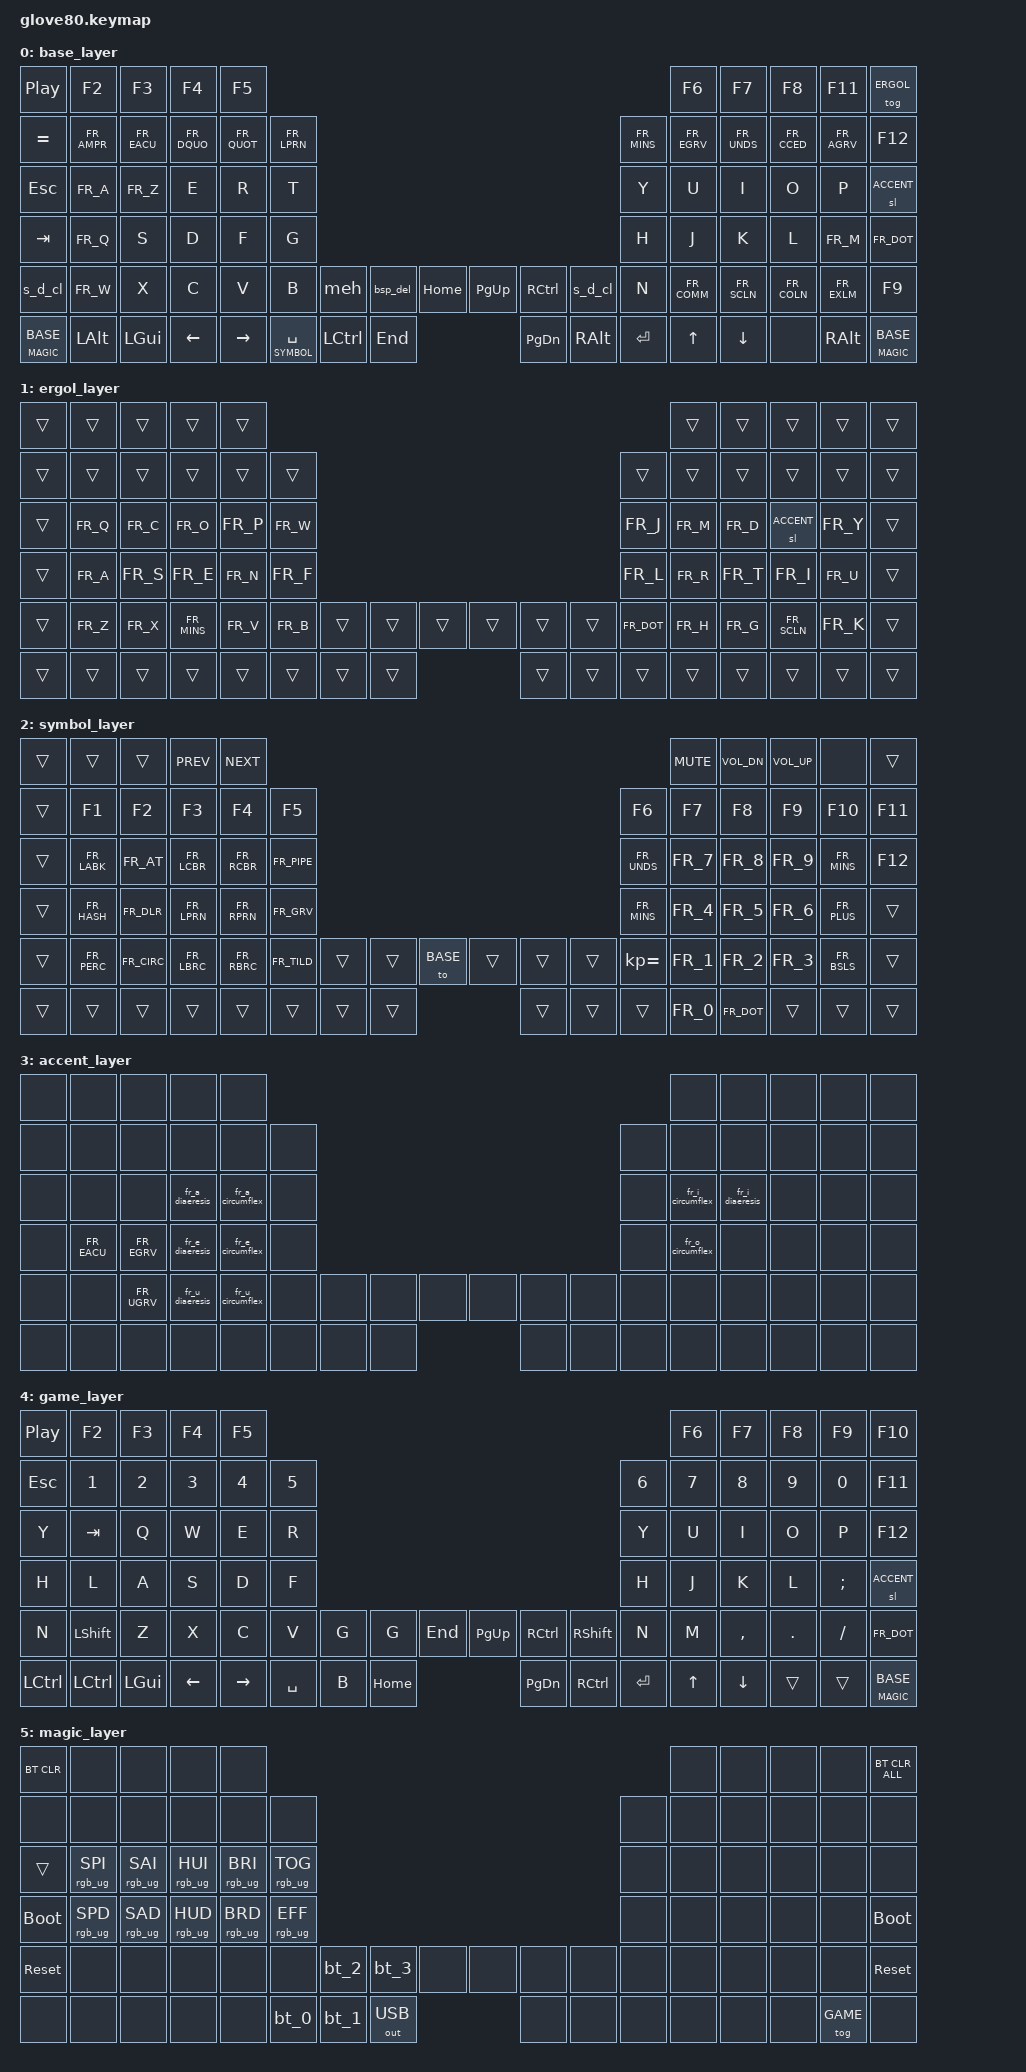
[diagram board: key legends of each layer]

/*
 * Copyright (c) 2020 The ZMK Contributors
 * Copyright (c) 2022 Innaworks Development Limited, trading as MoErgo
 *
 * SPDX-License-Identifier: MIT
 */


/* THIS FILE WAS GENERATED BY GLOVE80 LAYOUT EDITOR
 *
 * This file was generated automatically. You may or may not want to
 * edit it directly.
 */

#include <behaviors.dtsi>
/* Include all behaviour includes needed by system behaviors/macros */
#include <dt-bindings/zmk/outputs.h>

/* Include behaviour includes needed by key binds - automatically generated */
#include <dt-bindings/zmk/keys.h>
#include <dt-bindings/zmk/bt.h>
#include <dt-bindings/zmk/rgb.h>
#include <dt-bindings/zmk/outputs.h>


/* french helpers */
#ifndef KEYMAP_DRAWER
#include "keymap_french.h"
#endif

/*
Layers

Those numbers are meaningless.
The actual index of the layers is the one in keymap which are zero indexed.
*/
#define BASE    0
#define ERGOL   1
#define SYMBOL  2
#define ACCENT  3
#define GAME    4
#define MAGIC   5

/ {
    /* Glove80 system behavior & macros */
    behaviors {
        // For the "layer" key, it'd nice to be able to use it as either a shift or a toggle.
        // Configure it as a tap dance, so the first tap (or hold) is a &mo and the second tap is a &to
        lower: tap_dance_0 {
            compatible = "zmk,behavior-tap-dance";
            label = "LAYER_TAP_DANCE";
            #binding-cells = <0>;
            tapping-term-ms = <200>;
            bindings = <&mo SYMBOL>, <&to SYMBOL>;
        };

        s_d_cl: shift_double_capslock {
            compatible = "zmk,behavior-tap-dance";
            label = "shift_double_capslock";
            #binding-cells = <0>;
            tapping-term-ms = <200>;
            bindings = <&kp LSHIFT>, <&kp CAPSLOCK>;
        };

        bsp_del: backspace_delete {
            compatible = "zmk,behavior-mod-morph";
            #binding-cells = <0>;
            bindings = <&kp BSPC>, <&kp DEL>;
            mods = <(MOD_LSFT|MOD_RSFT)>;
        };
    };

    #define BT_MACRO(name)                  \
    bt_ ## name: bt_profile_macro_ ## name {\
        label = "BT_ ## name";              \
        compatible = "zmk,behavior-macro";  \
        #binding-cells = <0>;               \
        bindings                            \
            = <&out OUT_BLE>                \
            , <&bt BT_SEL name>;            \
    };

    macros {
        BT_MACRO(0)
        BT_MACRO(1)
        BT_MACRO(2)
        BT_MACRO(3)

        rgb_ug_status_macro: rgb_ug_status_macro_0 {
            label = "RGB_UG_STATUS";
            compatible = "zmk,behavior-macro";
            #binding-cells = <0>;
            bindings
                = <&rgb_ug RGB_STATUS>;
        };

        meh: meh_modifier {
            label = "MEH_MODIFIER";
            compatible = "zmk,behavior-macro";
            #binding-cells = <0>;
            bindings
                = <&macro_press &kp LS(LC(LALT))>
                , <&macro_pause_for_release>
                , <&macro_release &kp LS(LC(LALT))>
                ;
        };


    #define MACRO(name, keys)             \
    name: name##_macro {                  \
        label = #name;                    \
        compatible = "zmk,behavior-macro";\
        #binding-cells = <0>;             \
        tap-ms = <1>;                     \
        wait-ms = <1>;                    \
        bindings = <keys>;                \
    };

    // french accentuated letters
    #define diaeresis(name, key)    \
    MACRO(fr_ ## name ## _diaeresis, &kp FR_DIAE &kp key)

    #define circumflex(name, key)    \
    MACRO(fr_ ## name ## _circumflex, &kp FR_CIRC &kp key)

        circumflex(a, Q)
        circumflex(e, E)
        circumflex(i, I)
        circumflex(o, O)
        circumflex(u, U)
        diaeresis(a, Q)
        diaeresis(e, E)
        diaeresis(i, I)
        diaeresis(o, O)
        diaeresis(u, U)
    };

/* key positions for combos
From https://github.com/moergo-sc/zmk/blob/main/app/boards/arm/glove80/glove80.dtsi#L24-L29

0   1   2   3   4                                       5   6   7   8   9
10  11  12  13  14  15                              16  17  18  19  20  21
22  23  24  25  26  27                              38  39  50  31  32  33
34  35  36  37 (38) 39                              40 (41) 42  43  44  45  <- home row, and () are index
46  47  48  49  50  51    52 53 54    55  56  57    58  59  60  61  62  63
64  65  66  67  68        69 70 71    72  73  74        75  76  77  78  79

*/
/*
    combos {
      compatible = "zmk,combos";
      combo_ctrl_c {
        timeout-ms = <50>;
        // ring + middle finger on left hand
        key-positions = <36 37>;
        bindings = <&kp LC(C)>;
        layers = <BASE>;
      };
      combo_ctrl_v {
        timeout-ms = <50>;
        // middle finger + index on left hand
        key-positions = <37 38>;
        bindings = <&kp LC(V)>;
        layers = <BASE>;
      };
    };
*/

    magic: magic_hold_tap {
        compatible = "zmk,behavior-hold-tap";
        label = "MAGIC_HOLD_TAP";
        #binding-cells = <2>;
        flavor = "tap-preferred";
        tapping-term-ms = <200>;
        bindings = <&mo>, <&rgb_ug_status_macro>;
    };

    keymap {
        compatible = "zmk,keymap";

        base_layer {
            bindings = <
&kp C_PP          &kp F2      &kp F3      &kp F4      &kp F5                                                                                                         &kp F6      &kp F7      &kp F8      &kp F11     &tog ERGOL
&kp EQUAL         &kp FR_AMPR &kp FR_EACU &kp FR_DQUO &kp FR_QUOT &kp FR_LPRN                                                                        &kp FR_MINS &kp FR_EGRV &kp FR_UNDS &kp FR_CCED &kp FR_AGRV &kp F12
&kp ESC           &kp FR_A    &kp FR_Z    &kp E       &kp R       &kp T                                                                              &kp Y       &kp U       &kp I       &kp O       &kp P       &sl ACCENT
&kp TAB           &kp FR_Q    &kp S       &kp D       &kp F       &kp G                                                                              &kp H       &kp J       &kp K       &kp L       &kp FR_M    &kp FR_DOT
&s_d_cl           &kp FR_W    &kp X       &kp C       &kp V       &kp B     &meh             &bsp_del  &kp HOME    &kp PG_UP   &kp RCTRL   &s_d_cl   &kp N       &kp FR_COMM &kp FR_SCLN &kp FR_COLN &kp FR_EXLM &kp F9
&magic MAGIC BASE &kp LALT    &kp LGUI    &kp LEFT    &kp RIGHT             &lt SYMBOL SPACE &kp LCTRL &kp END     &kp PG_DN   &kp RALT    &kp RET                   &kp UP      &kp DOWN    &none       &kp RALT    &magic MAGIC BASE
            >;
        };

        ergol_layer {
            bindings = <
&trans     &trans     &trans     &trans       &trans                                                                                     &trans       &trans       &trans       &trans    &trans
&trans     &trans     &trans     &trans       &trans    &trans                                                               &trans      &trans       &trans       &trans       &trans    &trans
&trans     &kp FR_Q   &kp FR_C   &kp FR_O     &kp FR_P  &kp FR_W                                                             &kp FR_J    &kp FR_M     &kp FR_D     &sl ACCENT   &kp FR_Y  &trans
&trans     &kp FR_A   &kp FR_S   &kp FR_E     &kp FR_N  &kp FR_F                                                             &kp FR_L    &kp FR_R     &kp FR_T     &kp FR_I     &kp FR_U  &trans
&trans     &kp FR_Z   &kp FR_X   &kp FR_MINS  &kp FR_V  &kp FR_B   &trans   &trans  &trans        &trans   &trans   &trans   &kp FR_DOT  &kp FR_H     &kp FR_G     &kp FR_SCLN  &kp FR_K  &trans
&trans     &trans     &trans     &trans       &trans               &trans   &trans  &trans        &trans   &trans   &trans               &trans       &trans       &trans       &trans    &trans
            >;
        };

        symbol_layer {
            bindings = <
&trans  &trans          &trans      &kp C_PREV  &kp C_NEXT                                                                                            &kp C_MUTE  &kp C_VOL_DN    &kp C_VOL_UP    &none           &trans
&trans  &kp F1          &kp F2      &kp F3      &kp F4      &kp F5                                                                      &kp F6        &kp F7      &kp F8          &kp F9          &kp F10         &kp F11
&trans  &kp FR_LABK     &kp FR_AT   &kp FR_LCBR &kp FR_RCBR &kp FR_PIPE                                                                 &kp FR_UNDS   &kp FR_7    &kp FR_8        &kp FR_9        &kp FR_MINS     &kp F12
&trans  &kp FR_HASH     &kp FR_DLR  &kp FR_LPRN &kp FR_RPRN &kp FR_GRV                                                                  &kp FR_MINS   &kp FR_4    &kp FR_5        &kp FR_6        &kp FR_PLUS     &trans
&trans  &kp FR_PERC     &kp FR_CIRC &kp FR_LBRC &kp FR_RBRC &kp FR_TILD     &trans  &trans  &to BASE            &trans  &trans  &trans  &kp KP_EQUAL  &kp FR_1    &kp FR_2        &kp FR_3        &kp FR_BSLS     &trans
&trans  &trans          &trans     &trans      &trans                      &trans  &trans  &trans              &trans  &trans  &trans                &kp FR_0    &kp FR_DOT       &trans          &trans          &trans
            >;
        };

        accent_layer {
            bindings = <
&none       &none       &none       &none       &none                                                                                               &none           &none           &none       &none       &none
&none       &none       &none       &none       &none                   &none                                                           &none       &none           &none           &none       &none       &none
&none       &none       &none       &fr_a_diaeresis &fr_a_circumflex    &none                                                           &none       &fr_i_circumflex &fr_i_diaeresis&none       &none       &none
&none       &kp FR_EACU &kp FR_EGRV &fr_e_diaeresis &fr_e_circumflex    &none                                                           &none       &fr_o_circumflex &none          &none       &none       &none
&none       &none       &kp FR_UGRV &fr_u_diaeresis &fr_u_circumflex    &none       &none   &none   &none       &none   &none   &none   &none       &none           &none           &none       &none       &none
&none       &none       &none       &none       &none                               &none   &none   &none       &none   &none   &none               &none           &none           &none       &none       &none
            >;
        };

        game_layer {
            bindings = <
&kp C_PP    &kp F2      &kp F3   &kp F4    &kp F5                                                                                          &kp F6  &kp F7      &kp F8      &kp F9      &kp F10
&kp ESC     &kp N1      &kp N2   &kp N3    &kp N4    &kp N5                                                                        &kp N6  &kp N7  &kp N8      &kp N9      &kp N0      &kp F11
&kp Y       &kp TAB     &kp Q    &kp W     &kp E     &kp R                                                                         &kp Y   &kp U   &kp I       &kp O       &kp P       &kp F12
&kp H       &kp L       &kp A    &kp S     &kp D     &kp F                                                                         &kp H   &kp J   &kp K       &kp L       &kp SEMI    &sl ACCENT
&kp N       &kp LSHIFT  &kp Z    &kp X     &kp C     &kp V   &kp G     &kp G   &kp END         &kp PG_UP   &kp RCTRL   &kp RSHFT   &kp N   &kp M   &kp COMMA   &kp DOT     &kp FSLH    &kp FR_DOT
&kp LCTRL   &kp LCTRL   &kp LGUI &kp LEFT  &kp RIGHT         &kp SPACE &kp B   &kp HOME        &kp PG_DN   &kp RCTRL   &kp RET             &kp UP  &kp DOWN    &trans      &trans      &magic MAGIC BASE
            >;
        };

        magic_layer {
            bindings = <
&bt BT_CLR  &none            &none            &none            &none                                                                                                &none   &none   &none   &none   &bt BT_CLR_ALL
&none       &none            &none            &none            &none            &none                                                                       &none   &none   &none   &none   &none   &none
&trans      &rgb_ug RGB_SPI  &rgb_ug RGB_SAI  &rgb_ug RGB_HUI  &rgb_ug RGB_BRI  &rgb_ug RGB_TOG                                                             &none   &none   &none   &none   &none   &none
&bootloader &rgb_ug RGB_SPD  &rgb_ug RGB_SAD  &rgb_ug RGB_HUD  &rgb_ug RGB_BRD  &rgb_ug RGB_EFF                                                             &none   &none   &none   &none   &none   &bootloader
&sys_reset  &none            &none            &none            &none            &none           &bt_2   &bt_3  &none                &none   &none   &none   &none   &none   &none   &none   &none   &sys_reset
&none       &none            &none            &none            &none                            &bt_0   &bt_1  &out OUT_USB         &none   &none   &none           &none   &none   &none   &tog GAME &none
            >;
        };
        /*
        layer_template {
            bindings = <
&none       &none       &none       &none       &none                                                                               &none       &none       &none       &none       &none
&none       &none       &none       &none       &none   &none                                                           &none       &none       &none       &none       &none       &none
&none       &none       &none       &none       &none   &none                                                           &none       &none       &none       &none       &none       &none
&none       &none       &none       &none       &none   &none                                                           &none       &none       &none       &none       &none       &none
&none       &none       &none       &none       &none   &none       &none   &none  &none        &none   &none   &none   &none       &none       &none       &none       &none       &none
&none       &none       &none       &none       &none               &none   &none  &none        &none   &none   &none               &none       &none       &none       &none       &none
            >;
        };
        */

    };
};
